VERSION ""

BS_:

BU_: BITSET PC_SG

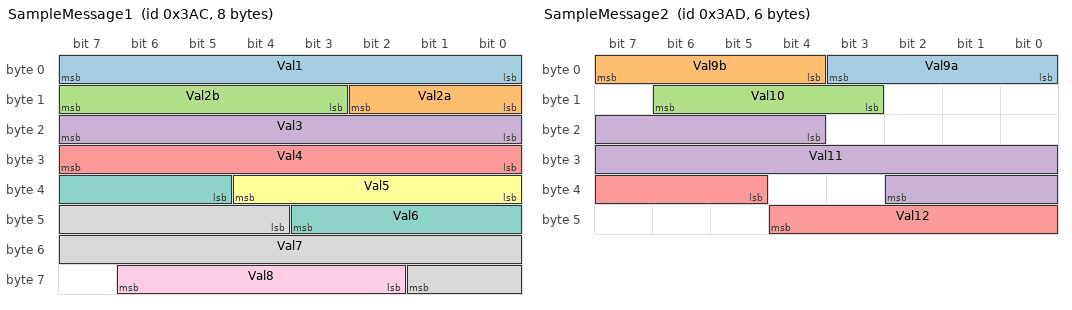
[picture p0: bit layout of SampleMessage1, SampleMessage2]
BO_ 940 SampleMessage1: 8 BITSET
    SG_ Val1 : 0|8@1+ (1,10) [0|1] "unitless" BITSET
    SG_ Val2a : 8|3@1+ (1,0) [0|1] "unitless" BITSET
    SG_ Val2b : 11|5@1+ (1,0) [0|1] "unitless" BITSET
    SG_ Val3 : 16|8@1+ (3,0) [0|1] "unitless" BITSET
    SG_ Val4 : 24|8@1+ (6,2) [0|1] "unitless" BITSET
    SG_ Val5 : 32|5@1+ (1,0) [0|1] "unitless" BITSET
    SG_ Val6 : 37|7@1+ (1,0) [0|1] "unitless" BITSET
    SG_ Val7 : 44|14@1+ (1,0) [0|1] "unitless" BITSET
    SG_ Val8 : 58|5@1+ (1,0) [0|1] "unitless" BITSET

BO_ 941 SampleMessage2: 6 BITSET
    SG_ Val9a : 0|4@1+ (3,5) [0|1] "unitless" BITSET
    SG_ Val9b : 4|4@1+ (4,6) [0|1] "unitless" BITSET
    SG_ Val10 : 11|4@1+ (5,12) [0|1] "unitless" BITSET
    SG_ Val11 : 20|15@1+ (6,4) [0|1] "unitless" BITSET
    SG_ Val12 : 37|8@1+ (7,3) [0|1] "unitless" BITSET
